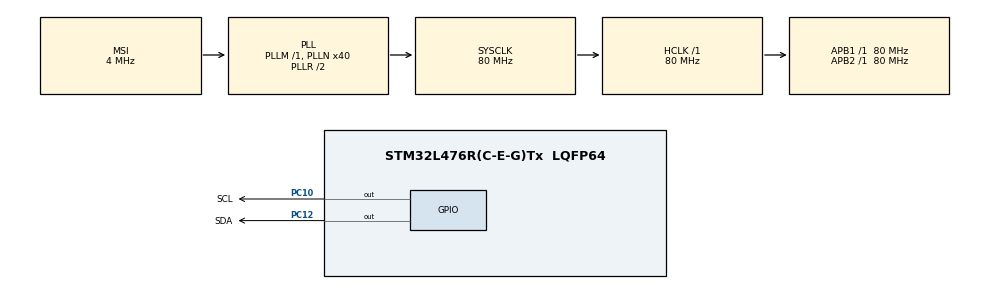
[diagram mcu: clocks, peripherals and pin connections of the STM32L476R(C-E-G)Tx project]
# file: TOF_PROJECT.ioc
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Mcu.Family=STM32L4
Mcu.Name=STM32L476R(C-E-G)Tx
Mcu.Package=LQFP64
NVIC.PriorityGroup=NVIC_PRIORITYGROUP_4
PA13\ (JTMS-SWDIO).Mode=Serial_Wire
PA13\ (JTMS-SWDIO).Signal=SYS_JTMS-SWDIO
PA14\ (JTCK-SWCLK).Mode=Serial_Wire
PA14\ (JTCK-SWCLK).Signal=SYS_JTCK-SWCLK
PC10.GPIO_Label=SCL
PC10.GPIO_ModeDefaultOutputPP=GPIO_MODE_OUTPUT_OD
PC10.GPIO_Speed=GPIO_SPEED_FREQ_HIGH
PC10.Signal=GPIO_Output
PC12.GPIO_Label=SDA
PC12.GPIO_ModeDefaultOutputPP=GPIO_MODE_OUTPUT_OD
PC12.GPIO_Speed=GPIO_SPEED_FREQ_HIGH
PC12.Signal=GPIO_Output
PH0-OSC_IN\ (PH0).Mode=HSE-External-Oscillator
PH0-OSC_IN\ (PH0).Signal=RCC_OSC_IN
PH1-OSC_OUT\ (PH1).Mode=HSE-External-Oscillator
PH1-OSC_OUT\ (PH1).Signal=RCC_OSC_OUT
ProjectManager.HeapSize=0x200
ProjectManager.StackSize=0x400
ProjectManager.TargetToolchain=MDK-ARM V5.27
RCC.AHBFreq_Value=80000000
RCC.APB1Freq_Value=80000000
RCC.APB1TimFreq_Value=80000000
RCC.APB2Freq_Value=80000000
RCC.APB2TimFreq_Value=80000000
RCC.CortexFreq_Value=80000000
RCC.HCLKFreq_Value=80000000
RCC.HSE_VALUE=8000000
RCC.HSI_VALUE=16000000
RCC.LSE_VALUE=32768
RCC.MSI_VALUE=4000000
RCC.PLLN=40
RCC.SYSCLKFreq_VALUE=80000000
RCC.SYSCLKSource=RCC_SYSCLKSOURCE_PLLCLK
RCC.VCOOutputFreq_Value=160000000
board=custom

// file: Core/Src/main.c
/* USER CODE BEGIN Header */
/**
  ******************************************************************************
  * @file           : main.c
  * @brief          : Main program body
  ******************************************************************************
  * @attention
  *
  * <h2><center>&copy; Copyright (c) 2021 STMicroelectronics.
  * All rights reserved.</center></h2>
  *
  * This software component is licensed by ST under BSD 3-Clause license,
  * the "License"; You may not use this file except in compliance with the
  * License. You may obtain a copy of the License at:
  *                        opensource.org/licenses/BSD-3-Clause
  *
  ******************************************************************************
  */
/* USER CODE END Header */
#include "main.h"
#include "gpio.h"

/* USER CODE BEGIN Includes */
#include "VL6180.h"
#include "bsp_i2c.h"
/* USER CODE END Includes */

void SystemClock_Config(void);

/* USER CODE BEGIN 0 */
int16_t init_flag = 0;
uint8_t range = 0;
uint8_t name;
float light;
/* USER CODE END 0 */

int main(void)
{

  /* MCU Configuration--------------------------------------------------------*/

  /* Reset of all peripherals, Initializes the Flash interface and the Systick. */
  HAL_Init();

  /* Configure the system clock */
  SystemClock_Config();

  /* Initialize all configured peripherals */
  MX_GPIO_Init();
  /* USER CODE BEGIN 2 */
   //init_flag =
   HAL_Delay(100);
   name = VL6180X_Read_ID();
   HAL_Delay(100);
   init_flag = VL6180X_Init();
   HAL_Delay(1000);

  /* USER CODE END 2 */

  /* Infinite loop */
  while (1)
  {

    /* USER CODE BEGIN 3 */
	range = VL6180X_Read_Range();
	HAL_Delay(1);
	light = VL6180X_Read_Lux(VL6180X_ALS_GAIN_1_25);

  }
  /* USER CODE END 3 */
}

void SystemClock_Config(void)
{
  RCC_OscInitTypeDef RCC_OscInitStruct = {0};
  RCC_ClkInitTypeDef RCC_ClkInitStruct = {0};

  /** Initializes the RCC Oscillators according to the specified parameters
  * in the RCC_OscInitTypeDef structure.
  */
  RCC_OscInitStruct.OscillatorType = RCC_OSCILLATORTYPE_MSI;
  RCC_OscInitStruct.MSIState = RCC_MSI_ON;
  RCC_OscInitStruct.MSICalibrationValue = 0;
  RCC_OscInitStruct.MSIClockRange = RCC_MSIRANGE_6;
  RCC_OscInitStruct.PLL.PLLState = RCC_PLL_ON;
  RCC_OscInitStruct.PLL.PLLSource = RCC_PLLSOURCE_MSI;
  RCC_OscInitStruct.PLL.PLLM = 1;
  RCC_OscInitStruct.PLL.PLLN = 40;
  RCC_OscInitStruct.PLL.PLLP = RCC_PLLP_DIV7;
  RCC_OscInitStruct.PLL.PLLQ = RCC_PLLQ_DIV2;
  RCC_OscInitStruct.PLL.PLLR = RCC_PLLR_DIV2;
  if (HAL_RCC_OscConfig(&RCC_OscInitStruct) != HAL_OK)
  {
    Error_Handler();
  }
  /** Initializes the CPU, AHB and APB buses clocks
  */
  RCC_ClkInitStruct.ClockType = RCC_CLOCKTYPE_HCLK|RCC_CLOCKTYPE_SYSCLK
                              |RCC_CLOCKTYPE_PCLK1|RCC_CLOCKTYPE_PCLK2;
  RCC_ClkInitStruct.SYSCLKSource = RCC_SYSCLKSOURCE_PLLCLK;
  RCC_ClkInitStruct.AHBCLKDivider = RCC_SYSCLK_DIV1;
  RCC_ClkInitStruct.APB1CLKDivider = RCC_HCLK_DIV1;
  RCC_ClkInitStruct.APB2CLKDivider = RCC_HCLK_DIV1;

  if (HAL_RCC_ClockConfig(&RCC_ClkInitStruct, FLASH_LATENCY_4) != HAL_OK)
  {
    Error_Handler();
  }
  /** Configure the main internal regulator output voltage
  */
  if (HAL_PWREx_ControlVoltageScaling(PWR_REGULATOR_VOLTAGE_SCALE1) != HAL_OK)
  {
    Error_Handler();
  }
}

void Error_Handler(void)
{
  __disable_irq();
  while (1)
  {
  }
}

/************************ (C) COPYRIGHT STMicroelectronics *****END OF FILE****/
